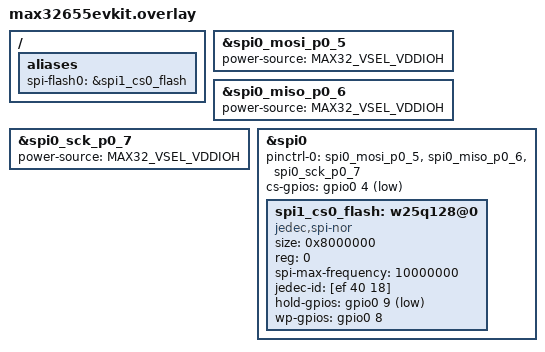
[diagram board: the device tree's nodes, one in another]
/*
 * Copyright (c) 2023 Analog Devices, Inc.
 *
 * SPDX-License-Identifier: Apache-2.0
 */

/ {
	aliases {
		spi-flash0 = &spi1_cs0_flash;
	};
};

&spi0_mosi_p0_5 {
	power-source = <MAX32_VSEL_VDDIOH>;
};

&spi0_miso_p0_6 {
	power-source = <MAX32_VSEL_VDDIOH>;
};

&spi0_sck_p0_7 {
	power-source = <MAX32_VSEL_VDDIOH>;
};

&spi0 {
	status = "okay";
	pinctrl-0 = <&spi0_mosi_p0_5 &spi0_miso_p0_6 &spi0_sck_p0_7>;
	pinctrl-names = "default";
	cs-gpios = <&gpio0 4 (GPIO_ACTIVE_LOW | MAX32_GPIO_VSEL_VDDIOH)>;

	spi1_cs0_flash: w25q128@0 {
		compatible = "jedec,spi-nor";
		/* 134217728 bits = 16 Mbytes */
		size = <0x8000000>;
		reg = <0>;
		spi-max-frequency = <10000000>;
		jedec-id = [ef 40 18];
		hold-gpios = <&gpio0 9 (GPIO_ACTIVE_LOW | MAX32_GPIO_VSEL_VDDIOH)>;
		wp-gpios = <&gpio0 8 (GPIO_ACTIVE_HIGH | MAX32_GPIO_VSEL_VDDIOH)>;
		status = "okay";
	};
};
